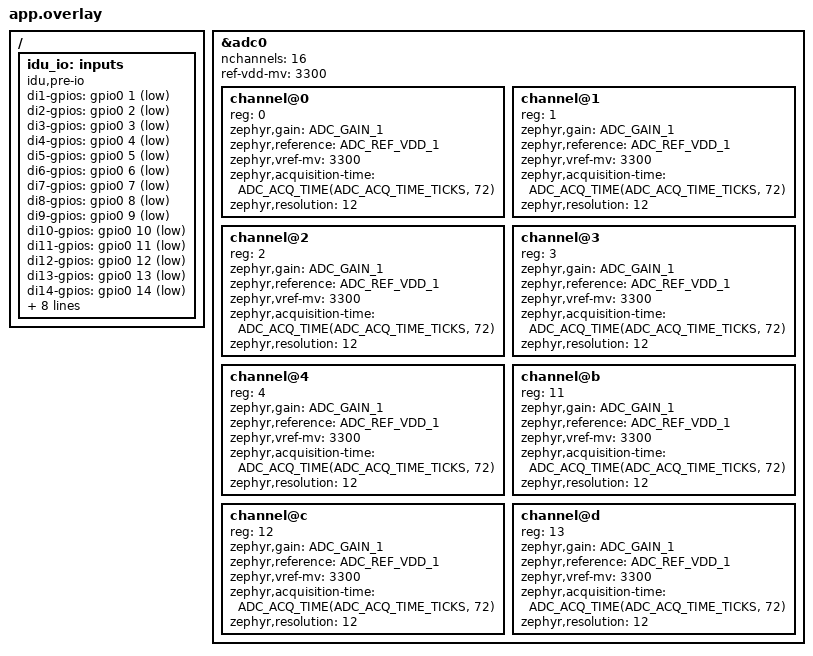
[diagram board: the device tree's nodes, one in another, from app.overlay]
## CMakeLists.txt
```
cmake_minimum_required(VERSION 3.20.0)
get_filename_component(IDU_APP ${CMAKE_CURRENT_SOURCE_DIR}/../.. ABSOLUTE)
list(APPEND DTS_ROOT ${IDU_APP})
list(APPEND ZEPHYR_EXTRA_MODULES ${IDU_APP}/modules/common)
find_package(Zephyr REQUIRED HINTS $ENV{ZEPHYR_BASE})
project(idu_adc_tests)
target_include_directories(app BEFORE PRIVATE fakes ../../app)
target_sources(app PRIVATE src/driver.c src/application.c ../../app/acquisition/acquisition.c)
# 测试原生 ADC 后端时，仍保留产品的十次采样契约。
target_compile_definitions(app PRIVATE CONFIG_IDU_ADC_AVERAGE_COUNT=10)

target_include_directories(app PRIVATE ../../modules/dataprocess/include)
```

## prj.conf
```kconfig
CONFIG_ZTEST=y
CONFIG_ADC=y
CONFIG_GPIO=y
CONFIG_ADC_ASYNC=y
CONFIG_CLOCK_CONTROL=y
CONFIG_RESET=y
CONFIG_NATIVE_SIM_SLOWDOWN_TO_REAL_TIME=n
```

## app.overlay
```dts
#include <zephyr/dt-bindings/adc/adc.h>
#include <zephyr/dt-bindings/gpio/gpio.h>
/ {
    idu_io: inputs {
        compatible = "idu,pre-io";
        di1-gpios = <&gpio0 1 GPIO_ACTIVE_LOW>;
        di2-gpios = <&gpio0 2 GPIO_ACTIVE_LOW>;
        di3-gpios = <&gpio0 3 GPIO_ACTIVE_LOW>;
        di4-gpios = <&gpio0 4 GPIO_ACTIVE_LOW>;
        di5-gpios = <&gpio0 5 GPIO_ACTIVE_LOW>;
        di6-gpios = <&gpio0 6 GPIO_ACTIVE_LOW>;
        di7-gpios = <&gpio0 7 GPIO_ACTIVE_LOW>;
        di8-gpios = <&gpio0 8 GPIO_ACTIVE_LOW>;
        di9-gpios = <&gpio0 9 GPIO_ACTIVE_LOW>;
        di10-gpios = <&gpio0 10 GPIO_ACTIVE_LOW>;
        di11-gpios = <&gpio0 11 GPIO_ACTIVE_LOW>;
        di12-gpios = <&gpio0 12 GPIO_ACTIVE_LOW>;
        di13-gpios = <&gpio0 13 GPIO_ACTIVE_LOW>;
        di14-gpios = <&gpio0 14 GPIO_ACTIVE_LOW>;
        di15-gpios = <&gpio0 15 GPIO_ACTIVE_LOW>;
        di16-gpios = <&gpio0 16 GPIO_ACTIVE_LOW>;
        address1-gpios = <&gpio0 17 GPIO_ACTIVE_LOW>;
        address2-gpios = <&gpio0 18 GPIO_ACTIVE_LOW>;
        address3-gpios = <&gpio0 19 GPIO_ACTIVE_LOW>;
        address4-gpios = <&gpio0 20 GPIO_ACTIVE_LOW>;
        io-channels = <&adc0 12>, <&adc0 1>, <&adc0 4>, <&adc0 13>, <&adc0 11>, <&adc0 0>, <&adc0 3>, <&adc0 2>;
        io-channel-names = "current-8", "current-3", "current-6", "current-1", "current-7", "current-2", "current-5", "current-4";
    };
};
&adc0 {
    nchannels = <16>;
    ref-vdd-mv = <3300>;
    #address-cells = <1>;
    #size-cells = <0>;
    channel@0 {
        reg = <0>;
        zephyr,gain = "ADC_GAIN_1";
        zephyr,reference = "ADC_REF_VDD_1";
        zephyr,vref-mv = <3300>;
        zephyr,acquisition-time = <ADC_ACQ_TIME(ADC_ACQ_TIME_TICKS, 72)>;
        zephyr,resolution = <12>;
    };
    channel@1 {
        reg = <1>;
        zephyr,gain = "ADC_GAIN_1";
        zephyr,reference = "ADC_REF_VDD_1";
        zephyr,vref-mv = <3300>;
        zephyr,acquisition-time = <ADC_ACQ_TIME(ADC_ACQ_TIME_TICKS, 72)>;
        zephyr,resolution = <12>;
    };
    channel@2 {
        reg = <2>;
        zephyr,gain = "ADC_GAIN_1";
        zephyr,reference = "ADC_REF_VDD_1";
        zephyr,vref-mv = <3300>;
        zephyr,acquisition-time = <ADC_ACQ_TIME(ADC_ACQ_TIME_TICKS, 72)>;
        zephyr,resolution = <12>;
    };
    channel@3 {
        reg = <3>;
        zephyr,gain = "ADC_GAIN_1";
        zephyr,reference = "ADC_REF_VDD_1";
        zephyr,vref-mv = <3300>;
        zephyr,acquisition-time = <ADC_ACQ_TIME(ADC_ACQ_TIME_TICKS, 72)>;
        zephyr,resolution = <12>;
    };
    channel@4 {
        reg = <4>;
        zephyr,gain = "ADC_GAIN_1";
        zephyr,reference = "ADC_REF_VDD_1";
        zephyr,vref-mv = <3300>;
        zephyr,acquisition-time = <ADC_ACQ_TIME(ADC_ACQ_TIME_TICKS, 72)>;
        zephyr,resolution = <12>;
    };
    channel@b {
        reg = <11>;
        zephyr,gain = "ADC_GAIN_1";
        zephyr,reference = "ADC_REF_VDD_1";
        zephyr,vref-mv = <3300>;
        zephyr,acquisition-time = <ADC_ACQ_TIME(ADC_ACQ_TIME_TICKS, 72)>;
        zephyr,resolution = <12>;
    };
    channel@c {
        reg = <12>;
        zephyr,gain = "ADC_GAIN_1";
        zephyr,reference = "ADC_REF_VDD_1";
        zephyr,vref-mv = <3300>;
        zephyr,acquisition-time = <ADC_ACQ_TIME(ADC_ACQ_TIME_TICKS, 72)>;
        zephyr,resolution = <12>;
    };
    channel@d {
        reg = <13>;
        zephyr,gain = "ADC_GAIN_1";
        zephyr,reference = "ADC_REF_VDD_1";
        zephyr,vref-mv = <3300>;
        zephyr,acquisition-time = <ADC_ACQ_TIME(ADC_ACQ_TIME_TICKS, 72)>;
        zephyr,resolution = <12>;
    };
};
```

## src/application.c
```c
#include <zephyr/ztest.h>
#include <zephyr/drivers/adc/adc_emul.h>
#include <zephyr/drivers/gpio/gpio_emul.h>
#include <acquisition/acquisition.h>

#include "protocol/inc/signal_keys.h"
#include <dataprocess/dataprocess.h>

static uint16_t di_value, current_values[SAMPLE_ANALOG_COUNT];
static unsigned updates;
static int set_error;

int dp_set_para(uint16_t device, uint16_t signal, const value_t *value)
{
    zassert_equal(device, DEVICE_LOCAL);
    if (set_error) {
        return set_error;
    }
    if (signal == SIGNAL_DI) {
        di_value = value->u16;
    } else {
        zassert_true(signal >= SIGNAL_CURRENT_1 && signal < SIGNAL_CURRENT_1 + SAMPLE_ANALOG_COUNT);
        current_values[signal - SIGNAL_CURRENT_1] = value->u16;
    }
    ++updates;
    return 0;
}

static const struct device *const emul = DEVICE_DT_GET(DT_NODELABEL(adc0));
static unsigned int samples[16];
static int fail_channel;
static int injected_raw;

static int sample_value(
    const struct device *dev, unsigned int channel, void *context, uint32_t *result)
{
    if ((int)channel == fail_channel) {
        return -EIO;
    }
    *result = injected_raw >= 0 ? injected_raw : channel * 100 + samples[channel];
    ++samples[channel];
    return 0;
}

static void before(void *fixture)
{
    memset(samples, 0, sizeof(samples));
    memset(current_values, 0, sizeof(current_values));
    updates = 0;
    set_error = 0;
    di_value = 0;
    fail_channel = -1;
    injected_raw = -1;
    for (unsigned int channel = 0; channel < 16; ++channel) {
        zassert_ok(adc_emul_raw_value_func_set(emul, channel, sample_value, NULL));
    }
    zassert_ok(acquisition_inputs_init());
}

ZTEST(adc_application, test_original_order_and_ten_sample_integer_average)
{
    const uint8_t order[] = {13, 0, 1, 2, 3, 4, 11, 12};
    const uint16_t expected[] = {21887, 67, 1745, 3424, 5102, 6781, 18530, 20208};
    zassert_ok(acquisition_cycle());
    zassert_equal(updates % 9, 0);
    for (unsigned int i = 0; i < ARRAY_SIZE(order); ++i) {
        zassert_equal(samples[order[i]], 10);
        zassert_equal(current_values[i], expected[i]);
    }
    zassert_equal(samples[5], 0);
}

ZTEST(adc_application, test_sampling_error_is_propagated_and_retry_works)
{
    fail_channel = 2;
    zassert_equal(acquisition_cycle(), -EIO);
    zassert_equal(updates, 4); /* DI 和前三路 AI 已写入，故障通道及后续点未更新。 */
    zassert_equal(samples[3], 0);
    fail_channel = -1;
    zassert_ok(acquisition_cycle());
    zassert_equal(updates, 13);
}

ZTEST(adc_application, test_digital_inputs_preserve_bit_order)
{
    const struct device *gpio = DEVICE_DT_GET(DT_NODELABEL(gpio0));
    /* 低电平有效的 DI1/DI16 合成为位图。 */
    zassert_ok(gpio_emul_input_set_masked(
        gpio, BIT_MASK(17) & ~BIT(0), BIT_MASK(17) & ~(BIT(0) | BIT(1) | BIT(16))));
    zassert_ok(acquisition_cycle());
    zassert_equal(di_value, 0x8001);
}

ZTEST(adc_application, test_each_digital_input_maps_to_its_bit)
{
    const struct device *gpio = DEVICE_DT_GET(DT_NODELABEL(gpio0));
    const uint32_t mask = BIT_MASK(17) & ~BIT(0);
    for (size_t i = 0; i < 16; ++i) {
        zassert_ok(gpio_emul_input_set_masked(gpio, mask, mask & ~BIT(i + 1)));
        zassert_ok(acquisition_cycle());
        zassert_equal(di_value, BIT(i));
    }
}

ZTEST(adc_application, test_point_write_failure_stops_before_adc_reads)
{
    set_error = -ENOMEM;
    zassert_equal(acquisition_cycle(), -ENOMEM);
    zassert_equal(updates, 0);
    for (size_t i = 0; i < ARRAY_SIZE(samples); ++i) {
        zassert_equal(samples[i], 0);
    }
}

ZTEST(adc_application, test_current_conversion_zero_midpoint_and_saturation)
{
    const uint16_t raw[] = {0, 1, 2048, 3904, 3905, 4095};
    const uint16_t expected[] = {0, 16, 34375, 65527, 65535, 65535};
    for (size_t n = 0; n < ARRAY_SIZE(raw); ++n) {
        injected_raw = raw[n];
        zassert_ok(acquisition_cycle());
        for (size_t i = 0; i < ARRAY_SIZE(current_values); ++i) {
            zassert_equal(current_values[i], expected[n]);
        }
    }
}

ZTEST_SUITE(adc_application, NULL, NULL, before, NULL, NULL);
```

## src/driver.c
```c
#include <zephyr/ztest.h>
/* 通过 adc_*() 测试真实后端，仅替换硬件。 */
#include "../../../modules/gd32e505/drivers/adc/adc_gd32e50x.c"

int test_pin_error;
static uint32_t ctl1, calibration_stall, bus_rate;
static bool conversion_stall, enabled;
static unsigned int conversions, resets, selected_channel, selected_time, selected_resolution;
static int clock_error, reset_error, clock_off_count;
static bool hold_conversion;
K_SEM_DEFINE(conversion_started, 0, 1);
K_SEM_DEFINE(conversion_release, 0, 1);

uint32_t *test_ctl1(void)
{
    ctl1 &= calibration_stall;
    if (ctl1) {
        k_busy_wait(1000); /* 外设卡住时推进 native_sim 时间。 */
    }
    return &ctl1;
}

void adc_deinit(uint32_t reg)
{
    ctl1 = 0;
    resets++;
}

void adc_mode_config(uint32_t mode)
{
}

void adc_special_function_config(uint32_t reg, uint32_t function, uint32_t enable)
{
}

void adc_data_alignment_config(uint32_t reg, uint32_t align)
{
}

void adc_channel_length_config(uint32_t reg, uint32_t group, uint32_t length)
{
}

void adc_external_trigger_source_config(uint32_t reg, uint32_t group, uint32_t source)
{
}

void adc_external_trigger_config(uint32_t reg, uint32_t group, uint32_t enable)
{
}

void adc_enable(uint32_t reg)
{
    enabled = true;
}

void adc_disable(uint32_t reg)
{
    enabled = false;
}

void adc_resolution_config(uint32_t reg, uint32_t resolution)
{
    selected_resolution = resolution;
}

void adc_regular_channel_config(uint32_t reg, uint32_t rank, uint32_t channel, uint32_t sample_time)
{
    selected_channel = channel;
    selected_time = sample_time;
}

void adc_flag_clear(uint32_t reg, uint32_t flag)
{
}

void adc_software_trigger_enable(uint32_t reg, uint32_t group)
{
    conversions++;
}

int adc_flag_get(uint32_t reg, uint32_t flag)
{
    if (hold_conversion) {
        hold_conversion = false;
        k_sem_give(&conversion_started);
        k_sem_take(&conversion_release, K_FOREVER);
    }
    if (conversion_stall) {
        k_busy_wait(1000);
    }
    return !conversion_stall;
}

uint16_t adc_regular_data_read(uint32_t reg)
{
    return 100 + selected_channel;
}

void rcu_adc_clock_config(uint32_t prescaler)
{
}

static int clock_on(const struct device *dev, clock_control_subsys_t sys)
{
    return clock_error;
}

static int clock_off(const struct device *dev, clock_control_subsys_t sys)
{
    clock_off_count++;
    return 0;
}

static int clock_rate(const struct device *dev, clock_control_subsys_t sys, uint32_t *rate)
{
    *rate = bus_rate;
    return 0;
}

static DEVICE_API(clock_control, clock_api) = {
    .on = clock_on,
    .off = clock_off,
    .get_rate = clock_rate,
};

static int reset_toggle(const struct device *dev, uint32_t id)
{
    return reset_error;
}

static DEVICE_API(reset, reset_api) = {.line_toggle = reset_toggle};
DEVICE_DEFINE(adc_test_clock, "adc_test_clock", NULL, NULL, NULL, NULL, POST_KERNEL, 1, &clock_api);
DEVICE_DEFINE(adc_test_reset, "adc_test_reset", NULL, NULL, NULL, NULL, POST_KERNEL, 1, &reset_api);
static struct gd32_adc_data test_data;
static struct gd32_adc_config test_config = {
    .reg = ADC0,
    .clock = DEVICE_GET(adc_test_clock),
    .reset = {.dev = DEVICE_GET(adc_test_reset)},
    .divisor = 6,
    .vdda_mv = 3300,
};
DEVICE_DEFINE(adc_under_test,
    "adc_under_test",
    NULL,
    NULL,
    &test_data,
    &test_config,
    POST_KERNEL,
    2,
    &gd32_adc_api);
static const struct device *const adc = DEVICE_GET(adc_under_test);
static const struct adc_channel_cfg channel = {
    .channel_id = 13,
    .gain = ADC_GAIN_1,
    .reference = ADC_REF_VDD_1,
    .acquisition_time = ADC_ACQ_TIME(ADC_ACQ_TIME_TICKS, 72),
};
static uint16_t buffer[2];
static struct adc_sequence sequence;

static void before(void *fixture)
{
    memset(&test_data, 0, sizeof(test_data));
    ctl1 = calibration_stall = conversions = resets = 0;
    conversion_stall = false;
    clock_error = reset_error = test_pin_error = clock_off_count = 0;
    bus_rate = 180000000;
    test_config.vdda_mv = 3300;
    test_config.divisor = 6;
    buffer[0] = buffer[1] = 0xcafe;
    sequence = (struct adc_sequence){
        .channels = BIT(13),
        .buffer = buffer,
        .buffer_size = sizeof(uint16_t),
        .resolution = 12,
    };
    zassert_ok(gd32_adc_init(adc));
    zassert_ok(adc_channel_setup(adc, &channel));
}

ZTEST(adc_driver, test_single_channel_and_buffer_boundary)
{
    zassert_ok(adc_read(adc, &sequence));
    zassert_equal(buffer[0], 113);
    zassert_equal(buffer[1], 0xcafe);
    zassert_equal(selected_channel, 13);
    zassert_equal(selected_time, ADC_SAMPLETIME_71POINT5);
    sequence.resolution = 10;
    zassert_ok(adc_read(adc, &sequence));
    zassert_equal(selected_resolution, ADC_RESOLUTION_10B);
}

ZTEST(adc_driver, test_reject_setup_without_affecting_existing_channel)
{
    struct adc_channel_cfg cfg = channel;
    cfg.channel_id = 16;
    zassert_equal(adc_channel_setup(adc, &cfg), -EINVAL);
    cfg = channel;
    cfg.gain = ADC_GAIN_2;
    zassert_equal(adc_channel_setup(adc, &cfg), -ENOTSUP);
    cfg = channel;
    cfg.reference = ADC_REF_INTERNAL;
    zassert_equal(adc_channel_setup(adc, &cfg), -ENOTSUP);
    cfg = channel;
    cfg.differential = true;
    zassert_equal(adc_channel_setup(adc, &cfg), -ENOTSUP);
    cfg = channel;
    cfg.acquisition_time = ADC_ACQ_TIME(ADC_ACQ_TIME_TICKS, 241);
    zassert_equal(adc_channel_setup(adc, &cfg), -ENOTSUP);
    cfg.acquisition_time = ADC_ACQ_TIME(ADC_ACQ_TIME_MICROSECONDS, 2);
    zassert_equal(adc_channel_setup(adc, &cfg), -ENOTSUP);
    zassert_ok(adc_read(adc, &sequence));
    zassert_equal(selected_time, ADC_SAMPLETIME_71POINT5);
}

ZTEST(adc_driver, test_reject_sequences_before_hardware_or_buffer_writes)
{
    sequence.channels = 0;
    zassert_equal(adc_read(adc, &sequence), -EINVAL);
    sequence.channels = BIT(16);
    zassert_equal(adc_read(adc, &sequence), -EINVAL);
    sequence.channels = BIT(13) | BIT(0);
    zassert_equal(adc_read(adc, &sequence), -ENOTSUP);
    sequence.channels = BIT(0); /* 有效物理通道，但未配置。 */
    zassert_equal(adc_read(adc, &sequence), -EINVAL);
    sequence.channels = BIT(13);
    sequence.buffer_size = 1;
    zassert_equal(adc_read(adc, &sequence), -ENOMEM);
    sequence.buffer_size = 2;
    sequence.resolution = 11;
    zassert_equal(adc_read(adc, &sequence), -EINVAL);
    sequence.resolution = 12;
    sequence.oversampling = 1;
    zassert_equal(adc_read(adc, &sequence), -ENOTSUP);
    sequence.oversampling = 0;
    sequence.options = &(struct adc_sequence_options){0};
    zassert_equal(adc_read(adc, &sequence), -ENOTSUP);
    sequence.options = NULL;
    sequence.buffer = NULL;
    zassert_equal(adc_read(adc, &sequence), -EINVAL);
    sequence.buffer = (uint8_t *)buffer + 1;
    zassert_equal(adc_read(adc, &sequence), -EINVAL);
    zassert_equal(conversions, 0);
    zassert_equal(buffer[0], 0xcafe);
    zassert_equal(buffer[1], 0xcafe);
}

ZTEST(adc_driver, test_conversion_timeout_recovers_without_stale_sample)
{
    conversion_stall = true;
    zassert_equal(adc_read(adc, &sequence), -ETIMEDOUT);
    zassert_equal(buffer[0], 0xcafe);
    zassert_false(enabled);
    zassert_false(test_data.calibrated);
    unsigned int previous_resets = resets;
    conversion_stall = false;
    zassert_ok(adc_read(adc, &sequence));
    zassert_true(resets > previous_resets);
    zassert_equal(buffer[0], 113);
}

ZTEST(adc_driver, test_calibration_timeouts_release_lock_and_recover)
{
    for (unsigned int stage = 0; stage < 2; ++stage) {
        calibration_stall = stage ? ADC_CTL1_CLB : ADC_CTL1_RSTCLB;
        sequence.calibrate = true;
        buffer[0] = 0xcafe;
        zassert_equal(adc_read(adc, &sequence), -ETIMEDOUT);
        zassert_equal(buffer[0], 0xcafe);
        zassert_false(enabled);
        calibration_stall = 0;
        sequence.calibrate = false;
        zassert_ok(adc_read(adc, &sequence));
        zassert_equal(buffer[0], 113);
    }
}

ZTEST(adc_driver, test_init_clock_limits_and_error_propagation)
{
    test_config.vdda_mv = 1800;
    zassert_equal(gd32_adc_init(adc), -EINVAL); /* 30 MHz 超过低电压下的限制。 */
    test_config.vdda_mv = 3300;
    test_config.divisor = 4;
    zassert_equal(gd32_adc_init(adc), -EINVAL); /* 45 MHz 超过 35 MHz。 */
    test_config.divisor = 6;
    test_pin_error = -EIO;
    zassert_equal(gd32_adc_init(adc), -EIO);
    test_pin_error = 0;
    clock_error = -EACCES;
    zassert_equal(gd32_adc_init(adc), -EACCES);
    clock_error = 0;
    reset_error = -EIO;
    zassert_equal(gd32_adc_init(adc), -EIO);
    zassert_equal(clock_off_count, 1);
    reset_error = 0;
    calibration_stall = ADC_CTL1_CLB;
    zassert_equal(gd32_adc_init(adc), -ETIMEDOUT);
    zassert_equal(clock_off_count, 2);
    zassert_false(enabled);
}

ZTEST(adc_driver, test_async_explicitly_unsupported)
{
    zassert_equal(adc_read_async(adc, &sequence, NULL), -ENOTSUP);
    zassert_equal(conversions, 0);
}

struct reader_result {
    uint32_t channel;
    uint16_t sample;
    int error;
};

K_THREAD_STACK_ARRAY_DEFINE(reader_stacks, 2, 2048);
static struct k_thread readers[2];

static void read_thread(void *arg, void *unused1, void *unused2)
{
    struct reader_result *result = arg;
    struct adc_sequence seq = {
        .channels = BIT(result->channel),
        .resolution = 12,
        .buffer = &result->sample,
        .buffer_size = sizeof(result->sample),
    };
    result->error = adc_read(adc, &seq);
}

ZTEST(adc_driver, test_concurrent_readers_cannot_change_inflight_channel)
{
    struct adc_channel_cfg cfg = channel;
    cfg.channel_id = 0;
    zassert_ok(adc_channel_setup(adc, &cfg));
    struct reader_result results[2] = {{.channel = 13}, {.channel = 0}};

    hold_conversion = true;
    k_thread_create(&readers[0],
        reader_stacks[0],
        K_THREAD_STACK_SIZEOF(reader_stacks[0]),
        read_thread,
        &results[0],
        NULL,
        NULL,
        5,
        0,
        K_NO_WAIT);
    zassert_ok(k_sem_take(&conversion_started, K_SECONDS(1)));
    k_thread_create(&readers[1],
        reader_stacks[1],
        K_THREAD_STACK_SIZEOF(reader_stacks[1]),
        read_thread,
        &results[1],
        NULL,
        NULL,
        5,
        0,
        K_NO_WAIT);
    k_sleep(K_MSEC(1));
    zassert_equal(conversions, 1);
    zassert_equal(selected_channel, 13);
    k_sem_give(&conversion_release);
    for (unsigned int i = 0; i < 2; ++i) {
        zassert_ok(k_thread_join(&readers[i], K_SECONDS(1)));
        zassert_ok(results[i].error);
    }
    zassert_equal(results[0].sample, 113);
    zassert_equal(results[1].sample, 100);
}

ZTEST_SUITE(adc_driver, NULL, NULL, before, NULL, NULL);
```
